# TMS320F280049 register map
Vendor: Texas Instruments; Series: C2000 F28004x; File version: 0.2.0-generated
Registers are 16-bit, read-write, reset 0x0 unless marked. A register's access mark holds for its fields unless they carry their own. Offsets are from the block's base; [hi:lo] are bit positions; {n}, {i} and the like mark numbered series.

## XBARREGS — XBAR Registers
Base 0x0000F240
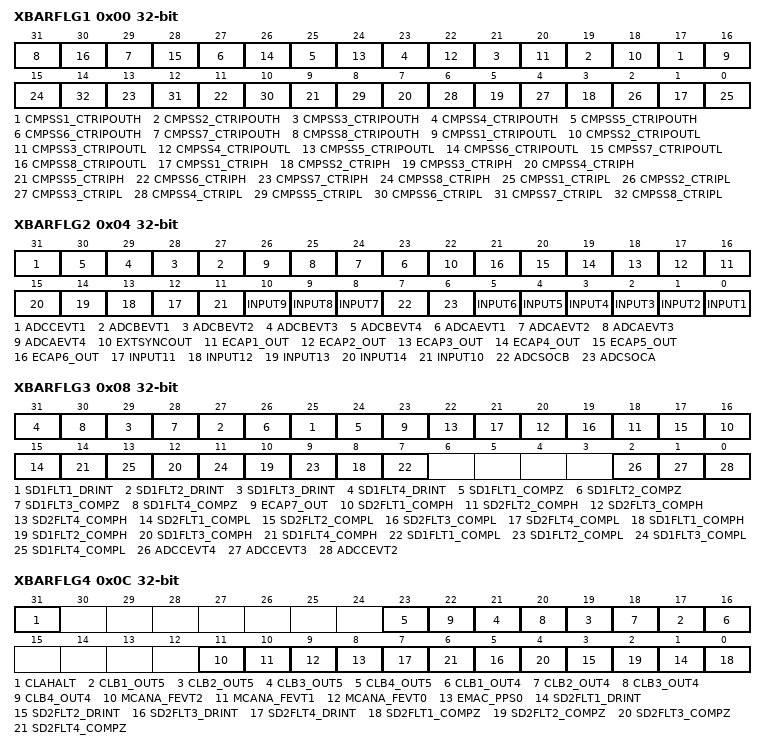
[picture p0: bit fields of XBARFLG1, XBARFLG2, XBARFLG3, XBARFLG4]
0x00 XBARFLG1 32-bit — X-Bar Input Flag Register 1
  [2n+15] CMPSS{n}_CTRIPOUTH (n=1..8) — Input Flag for CMPSS{n}.CTRIPOUTH Signal
  [2n+14] CMPSS{n}_CTRIPOUTL (n=1..8) — Input Flag for CMPSS{n}.CTRIPOUTL Signal
  [2n-1] CMPSS{n}_CTRIPH (n=1..8) — Input Flag for CMPSS{n}.CTRIPH Signal
  [2n-2] CMPSS{n}_CTRIPL (n=1..8) — Input Flag for CMPSS{n}.CTRIPL Signal
0x04 XBARFLG2 32-bit — X-Bar Input Flag Register 2
  [31] ADCCEVT1 — Input Flag for ADCCEVT1 Signal
  [n+26] ADCBEVT{n} (n=1..4) — Input Flag for ADCBEVT{n} Signal
  [n+22] ADCAEVT{n} (n=1..4) — Input Flag for ADCAEVT{n} Signal
  [22] EXTSYNCOUT — Input Flag for EXTSYNCOUT Signal
  [n+15] ECAP{n}_OUT (n=1..6) — Input Flag for ECAP{n}.OUT Signal
  [n+1] INPUT{n} (n=11..14) — Input Flag for INPUT{n} Signal
  [11] INPUT10 — Input Flag for INPUT10\ Signal
  [10] INPUT9 — Input Flag for INPUT9 Signal
  [9] INPUT8 — Input Flag for INPUT8 Signal
  [8] INPUT7 — Input Flag for INPUT7 Signal
  [7] ADCSOCB — Input Flag for ADCSOCB Signal
  [6] ADCSOCA — Input Flag for ADCSOCA Signal
  [n-1] INPUT{n} (n=1..6) — Input Flag for INPUT{n} Signal
0x08 XBARFLG3 32-bit — X-Bar Input Flag Register 3
  [2n+23] SD1FLT{n}_DRINT (n=1..4) — Input Flag for SD1FLT{n}.DRINT Signal
  [2n+22] SD1FLT{n}_COMPZ (n=1..4) — Input Flag for SD1FLT{n}.COMPZ Signal
  [23] ECAP7_OUT — Input Flag for ECAP7.OUT Signal
  [2n+14] SD2FLT{n}_COMPH (n=1..4) — Input Flag for SD2FLT{n}.COMPH Signal
  [2n+13] SD2FLT{n}_COMPL (n=1..4) — Input Flag for SD2FLT{n}.COMPL Signal
  [2n+6] SD1FLT{n}_COMPH (n=1..4) — Input Flag for SD1FLT{n}.COMPH Signal
  [2n+5] SD1FLT{n}_COMPL (n=1..4) — Input Flag for SD1FLT{n}.COMPL Signal
  [2] ADCCEVT4 — Input Flag for ADCCEVT4 Signal
  [1] ADCCEVT3 — Input Flag for ADCCEVT3 Signal
  [0] ADCCEVT2 — Input Flag for ADCCEVT2 Signal
0x0C XBARFLG4 32-bit — X-Bar Input Flag Register 4
  [31] CLAHALT — Input Latch for CLAHALT Signal
  [2n+15] CLB{n}_OUT5 (n=1..4) — Input Flag for CLB{n}_OUT5 Signal
  [2n+14] CLB{n}_OUT4 (n=1..4) — Input Flag for CLB{n}_OUT4 Signal
  [11] MCANA_FEVT2 — Input Flag for MCANA_FEVT2 Signal
  [10] MCANA_FEVT1 — Input Flag for MCANA_FEVT1 Signal
  [9] MCANA_FEVT0 — Input Flag for MCANA_FEVT0 Signal
  [8] EMAC_PPS0 — Input Flag for EMAC_PPS0 Signal
  [2n-1] SD2FLT{n}_DRINT (n=1..4) — Input Flag for SD2FLT{n}.DRINT Signal
  [2n-2] SD2FLT{n}_COMPZ (n=1..4) — Input Flag for SD2FLT{n}.COMPZ Signal
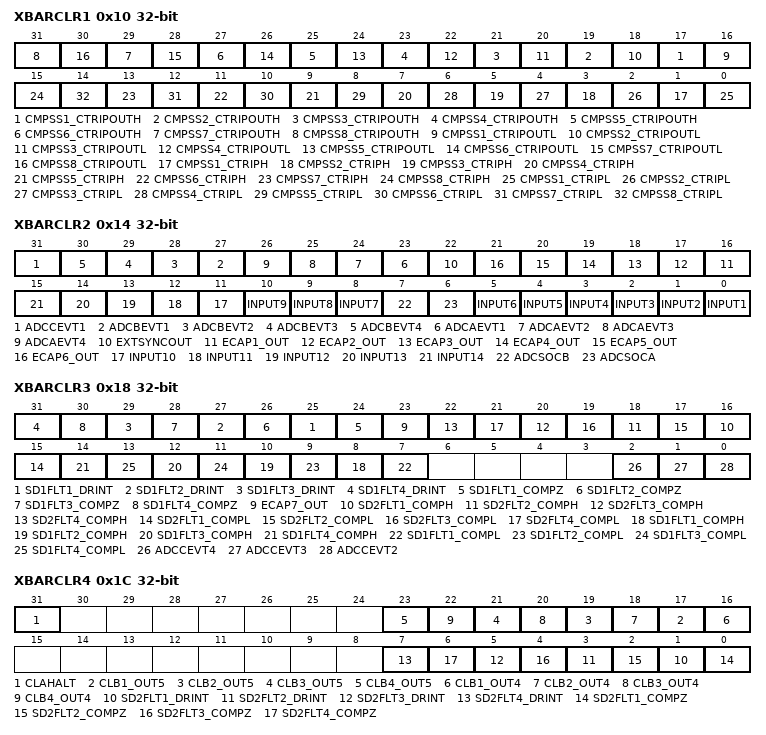
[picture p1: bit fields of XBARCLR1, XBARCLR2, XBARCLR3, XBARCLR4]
0x10 XBARCLR1 32-bit — X-Bar Input Flag Clear Register 1
  [2n+15] CMPSS{n}_CTRIPOUTH (n=1..8) — Input Flag Clear for CMPSS{n}.CTRIPOUTH Signal
  [2n+14] CMPSS{n}_CTRIPOUTL (n=1..8) — Input Flag Clear for CMPSS{n}.CTRIPOUTL Signal
  [2n-1] CMPSS{n}_CTRIPH (n=1..8) — Input Flag Clear for CMPSS{n}.CTRIPH Signal
  [2n-2] CMPSS{n}_CTRIPL (n=1..8) — Input Flag Clear for CMPSS{n}.CTRIPL Signal
0x14 XBARCLR2 32-bit — X-Bar Input Flag Clear Register 2
  [31] ADCCEVT1 — Input Flag Clear for ADCCEVT1 Signal
  [n+26] ADCBEVT{n} (n=1..4) — Input Flag Clear for ADCBEVT{n} Signal
  [n+22] ADCAEVT{n} (n=1..4) — Input Flag Clear for ADCAEVT{n} Signal
  [22] EXTSYNCOUT — Input Flag Clear for EXTSYNCOUT Signal
  [n+15] ECAP{n}_OUT (n=1..6) — Input Flag Clear for ECAP{n}.OUT Signal
  [n+1] INPUT{n} (n=7..14) — Input Flag Clear for INPUT{n} Signal
  [7] ADCSOCB — Input Flag Clear for ADCSOCB Signal
  [6] ADCSOCA — Input Flag Clear for ADCSOCA Signal
  [n-1] INPUT{n} (n=1..6) — Input Flag Clear for INPUT{n} Signal
0x18 XBARCLR3 32-bit — X-Bar Input Flag Clear Register 3
  [2n+23] SD1FLT{n}_DRINT (n=1..4) — Input Flag clear for SD1FLT{n}.DRINT Signal
  [2n+22] SD1FLT{n}_COMPZ (n=1..4) — Input Flag clear for SD1FLT{n}.COMPZ Signal
  [23] ECAP7_OUT — Input Flag clear for ECAP7.OUT Signal
  [2n+14] SD2FLT{n}_COMPH (n=1..4) — Input Flag Clear for SD2FLT{n}.COMPH Signal
  [2n+13] SD2FLT{n}_COMPL (n=1..4) — Input Flag Clear for SD2FLT{n}.COMPL Signal
  [2n+6] SD1FLT{n}_COMPH (n=1..4) — Input Flag Clear for SD1FLT{n}.COMPH Signal
  [2n+5] SD1FLT{n}_COMPL (n=1..4) — Input Flag Clear for SD1FLT{n}.COMPL Signal
  [2] ADCCEVT4 — Input Flag Clear for ADCCEVT4 Signal
  [1] ADCCEVT3 — Input Flag Clear for ADCCEVT3 Signal
  [0] ADCCEVT2 — Input Flag Clear for ADCCEVT2 Signal
0x1C XBARCLR4 32-bit — X-Bar Input Flag Clear Register 4
  [31] CLAHALT — Input Flag clear for CLAHALT Signal
  [2n+15] CLB{n}_OUT5 (n=1..4) — Input Flag clear for CLB{n}_OUT5 Signal
  [2n+14] CLB{n}_OUT4 (n=1..4) — Input Flag clear for CLB{n}_OUT4 Signal
  [2n-1] SD2FLT{n}_DRINT (n=1..4) — Input Flag clear for SD2FLT{n}.DRINT Signal
  [2n-2] SD2FLT{n}_COMPZ (n=1..4) — Input Flag clear for SD2FLT{n}.COMPZ Signal
